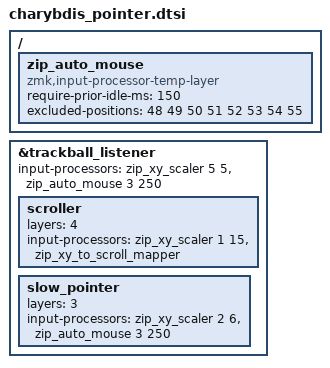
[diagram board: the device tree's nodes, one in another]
#include <input/processors.dtsi>
#include <dt-bindings/zmk/input_transform.h>

/ {
    /* Auto mouse layer: turn on MOUSE (layer 3) when the trackball moves,
       drop it again after the timeout with no movement. */
    zip_auto_mouse: zip_auto_mouse {
        compatible = "zmk,input-processor-temp-layer";
        #input-processor-cells = <2>;
        require-prior-idle-ms = <150>;                   // don't pop up while you're typing
        excluded-positions = <48 49 50 51 52 53 54 55>;  // thumb click keys shouldn't drop the layer
    };
};

&trackball_listener {
    /* base processor chain on all layers */
    input-processors = <&zip_xy_scaler 5 5 &zip_auto_mouse 3 250>;

    /* layer-4 scroll override */
    scroller: scroller {
        layers           = <4>;
        input-processors = <
            &zip_xy_scaler 1 15                     // scroll speed
            &zip_xy_to_scroll_mapper                // XY movement -> scroll
        >;
    };

    /* layer-3 slow-pointer override (MOUSE layer) — keep the temp layer alive while moving */
    slow_pointer: slow_pointer {
        layers           = <3>;
        input-processors = <&zip_xy_scaler 2 6 &zip_auto_mouse 3 250>;
    };
};
